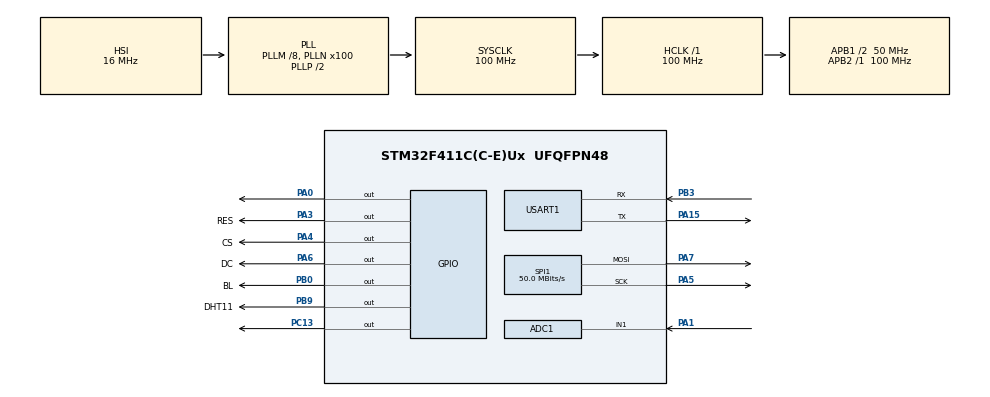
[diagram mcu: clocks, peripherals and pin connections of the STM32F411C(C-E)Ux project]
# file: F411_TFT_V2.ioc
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ADC1.Channel-0\#ChannelRegularConversion=ADC_CHANNEL_1
ADC1.Channel-1\#ChannelRegularConversion=ADC_CHANNEL_TEMPSENSOR
ADC1.Channel-2\#ChannelRegularConversion=ADC_CHANNEL_1
ADC1.NbrOfConversion=3
ADC1.NbrOfConversionFlag=1
ADC1.Rank-0\#ChannelRegularConversion=1
ADC1.Rank-1\#ChannelRegularConversion=2
ADC1.Rank-2\#ChannelRegularConversion=3
ADC1.SamplingTime-0\#ChannelRegularConversion=ADC_SAMPLETIME_480CYCLES
ADC1.SamplingTime-1\#ChannelRegularConversion=ADC_SAMPLETIME_480CYCLES
ADC1.SamplingTime-2\#ChannelRegularConversion=ADC_SAMPLETIME_480CYCLES
ADC1.ScanConvMode=ENABLE
ADC1.master=1
Dma.Request0=SPI1_TX
Dma.SPI1_TX.0.Direction=DMA_MEMORY_TO_PERIPH
Dma.SPI1_TX.0.FIFOMode=DMA_FIFOMODE_DISABLE
Dma.SPI1_TX.0.Instance=DMA2_Stream2
Dma.SPI1_TX.0.MemDataAlignment=DMA_MDATAALIGN_BYTE
Dma.SPI1_TX.0.MemInc=DMA_MINC_ENABLE
Dma.SPI1_TX.0.Mode=DMA_NORMAL
Dma.SPI1_TX.0.PeriphDataAlignment=DMA_PDATAALIGN_BYTE
Dma.SPI1_TX.0.PeriphInc=DMA_PINC_DISABLE
Dma.SPI1_TX.0.Priority=DMA_PRIORITY_LOW
Mcu.Family=STM32F4
Mcu.Name=STM32F411C(C-E)Ux
Mcu.Package=UFQFPN48
NVIC.DMA2_Stream2_IRQn=true\:0\:0\:false\:false\:true\:false\:true\:true
NVIC.PriorityGroup=NVIC_PRIORITYGROUP_4
NVIC.TIM1_TRG_COM_TIM11_IRQn=true\:0\:0\:false\:false\:true\:true\:true\:true
PA0-WKUP.Signal=GPIO_Output
PA1.Signal=ADCx_IN1
PA13.Mode=Serial_Wire
PA13.Signal=SYS_JTMS-SWDIO
PA14.Mode=Serial_Wire
PA14.Signal=SYS_JTCK-SWCLK
PA15.Mode=Asynchronous
PA15.Signal=USART1_TX
PA3.GPIO_Label=RES
PA3.Signal=GPIO_Output
PA4.GPIO_Label=CS
PA4.Signal=GPIO_Output
PA5.Mode=TX_Only_Simplex_Unidirect_Master
PA5.Signal=SPI1_SCK
PA6.GPIO_Label=DC
PA6.Signal=GPIO_Output
PA7.Mode=TX_Only_Simplex_Unidirect_Master
PA7.Signal=SPI1_MOSI
PB0.GPIO_Label=BL
PB0.Signal=GPIO_Output
PB3.Mode=Asynchronous
PB3.Signal=USART1_RX
PB9.GPIO_Label=DHT11
PB9.Signal=GPIO_Output
PC13-ANTI_TAMP.Signal=GPIO_Output
PC14-OSC32_IN.Mode=LSE-External-Oscillator
PC14-OSC32_IN.Signal=RCC_OSC32_IN
PC15-OSC32_OUT.Mode=LSE-External-Oscillator
PC15-OSC32_OUT.Signal=RCC_OSC32_OUT
PH0\ -\ OSC_IN.Mode=HSE-External-Oscillator
PH0\ -\ OSC_IN.Signal=RCC_OSC_IN
PH1\ -\ OSC_OUT.Mode=HSE-External-Oscillator
PH1\ -\ OSC_OUT.Signal=RCC_OSC_OUT
ProjectManager.HeapSize=0x200
ProjectManager.StackSize=0x400
ProjectManager.TargetToolchain=MDK-ARM V5.32
RCC.48MHZClocksFreq_Value=50000000
RCC.AHBFreq_Value=100000000
RCC.APB1CLKDivider=RCC_HCLK_DIV2
RCC.APB1Freq_Value=50000000
RCC.APB1TimFreq_Value=100000000
RCC.APB2Freq_Value=100000000
RCC.APB2TimFreq_Value=100000000
RCC.CortexFreq_Value=100000000
RCC.HCLKFreq_Value=100000000
RCC.HSE_VALUE=25000000
RCC.HSI_VALUE=16000000
RCC.PLLM=8
RCC.PLLN=100
RCC.SYSCLKFreq_VALUE=100000000
RCC.SYSCLKSource=RCC_SYSCLKSOURCE_PLLCLK
RCC.VCOOutputFreq_Value=200000000
SH.ADCx_IN1.0=ADC1_IN1,IN1
SPI1.BaudRatePrescaler=SPI_BAUDRATEPRESCALER_2
SPI1.CalculateBaudRate=50.0 MBits/s
SPI1.Direction=SPI_DIRECTION_2LINES
SPI1.Mode=SPI_MODE_MASTER
SPI1.VirtualType=VM_MASTER
TIM10.Prescaler=100-1
TIM11.Period=2000-1
TIM11.Prescaler=1000-1
TIM9.Prescaler=10000-1
USART1.VirtualMode=VM_ASYNC
VP_ADC1_TempSens_Input.Mode=IN-TempSens
VP_ADC1_Vref_Input.Mode=IN-Vrefint
VP_TIM10_VS_ClockSourceINT.Mode=Enable_Timer
VP_TIM11_VS_ClockSourceINT.Mode=Enable_Timer
VP_TIM9_VS_ClockSourceINT.Mode=Internal
board=custom

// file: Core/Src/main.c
/* USER CODE BEGIN Header */
/**
  ******************************************************************************
  * @file           : main.c
  * @brief          : Main program body
  ******************************************************************************
  * @attention
  *
  * Copyright (c) 2025 STMicroelectronics.
  * All rights reserved.
  *
  * This software is licensed under terms that can be found in the LICENSE file
  * in the root directory of this software component.
  * If no LICENSE file comes with this software, it is provided AS-IS.
  *
  ******************************************************************************
  */
/* USER CODE END Header */
#include "main.h"
#include "adc.h"
#include "dma.h"
#include "spi.h"
#include "tim.h"
#include "usart.h"
#include "gpio.h"

/* USER CODE BEGIN Includes */
#include "app_scheduler.h"
#include "app_tasks.h"
#include "Key.h"
#include <stdio.h>

int fputc(int ch, FILE *f)
{
    Log_WriteChar((char)ch);
    if (ch == '\n') {
        Log_WriteChar('\r');
    }
    return ch;
}
/* USER CODE END Includes */

/* USER CODE BEGIN PTD */
/* 状态和数据结构已迁移至 app_data.h / app_tasks.h */
/* USER CODE END PTD */

void SystemClock_Config(void);
/* USER CODE BEGIN PFP */
/* 业务逻辑函数已迁移至 app_scheduler.c / app_tasks.c */
/* USER CODE END PFP */

int main(void)
{

  /* MCU Configuration--------------------------------------------------------*/

  /* Reset of all peripherals, Initializes the Flash interface and the Systick. */
  HAL_Init();

  /* Configure the system clock */
  SystemClock_Config();

  /* Initialize all configured peripherals */
  MX_GPIO_Init();
  MX_DMA_Init();
  MX_SPI1_Init();
  MX_TIM10_Init();
  MX_TIM9_Init();
  MX_TIM11_Init();
  MX_ADC1_Init();
  MX_USART1_UART_Init();
  /* USER CODE BEGIN 2 */

  App_Init();

  /* USER CODE END 2 */

  /* Infinite loop */
  while (1)
  {

    /* USER CODE BEGIN 3 */
    App_Run();
  }
  /* USER CODE END 3 */
}

void SystemClock_Config(void)
{
  RCC_OscInitTypeDef RCC_OscInitStruct = {0};
  RCC_ClkInitTypeDef RCC_ClkInitStruct = {0};

  /** Configure the main internal regulator output voltage
  */
  __HAL_RCC_PWR_CLK_ENABLE();
  __HAL_PWR_VOLTAGESCALING_CONFIG(PWR_REGULATOR_VOLTAGE_SCALE1);

  /** Initializes the RCC Oscillators according to the specified parameters
  * in the RCC_OscInitTypeDef structure.
  */
  RCC_OscInitStruct.OscillatorType = RCC_OSCILLATORTYPE_HSI;
  RCC_OscInitStruct.HSIState = RCC_HSI_ON;
  RCC_OscInitStruct.HSICalibrationValue = RCC_HSICALIBRATION_DEFAULT;
  RCC_OscInitStruct.PLL.PLLState = RCC_PLL_ON;
  RCC_OscInitStruct.PLL.PLLSource = RCC_PLLSOURCE_HSI;
  RCC_OscInitStruct.PLL.PLLM = 8;
  RCC_OscInitStruct.PLL.PLLN = 100;
  RCC_OscInitStruct.PLL.PLLP = RCC_PLLP_DIV2;
  RCC_OscInitStruct.PLL.PLLQ = 4;
  if (HAL_RCC_OscConfig(&RCC_OscInitStruct) != HAL_OK)
  {
    Error_Handler();
  }

  /** Initializes the CPU, AHB and APB buses clocks
  */
  RCC_ClkInitStruct.ClockType = RCC_CLOCKTYPE_HCLK|RCC_CLOCKTYPE_SYSCLK
                              |RCC_CLOCKTYPE_PCLK1|RCC_CLOCKTYPE_PCLK2;
  RCC_ClkInitStruct.SYSCLKSource = RCC_SYSCLKSOURCE_PLLCLK;
  RCC_ClkInitStruct.AHBCLKDivider = RCC_SYSCLK_DIV1;
  RCC_ClkInitStruct.APB1CLKDivider = RCC_HCLK_DIV2;
  RCC_ClkInitStruct.APB2CLKDivider = RCC_HCLK_DIV1;

  if (HAL_RCC_ClockConfig(&RCC_ClkInitStruct, FLASH_LATENCY_3) != HAL_OK)
  {
    Error_Handler();
  }
}

/* USER CODE BEGIN 4 */
void HAL_TIM_PeriodElapsedCallback(TIM_HandleTypeDef *htim)
{
    if (htim->Instance == TIM11)
    {
        key_scan();
    }
}
/* USER CODE END 4 */

void Error_Handler(void)
{
  __disable_irq();
  while (1)
  {
  }
}
